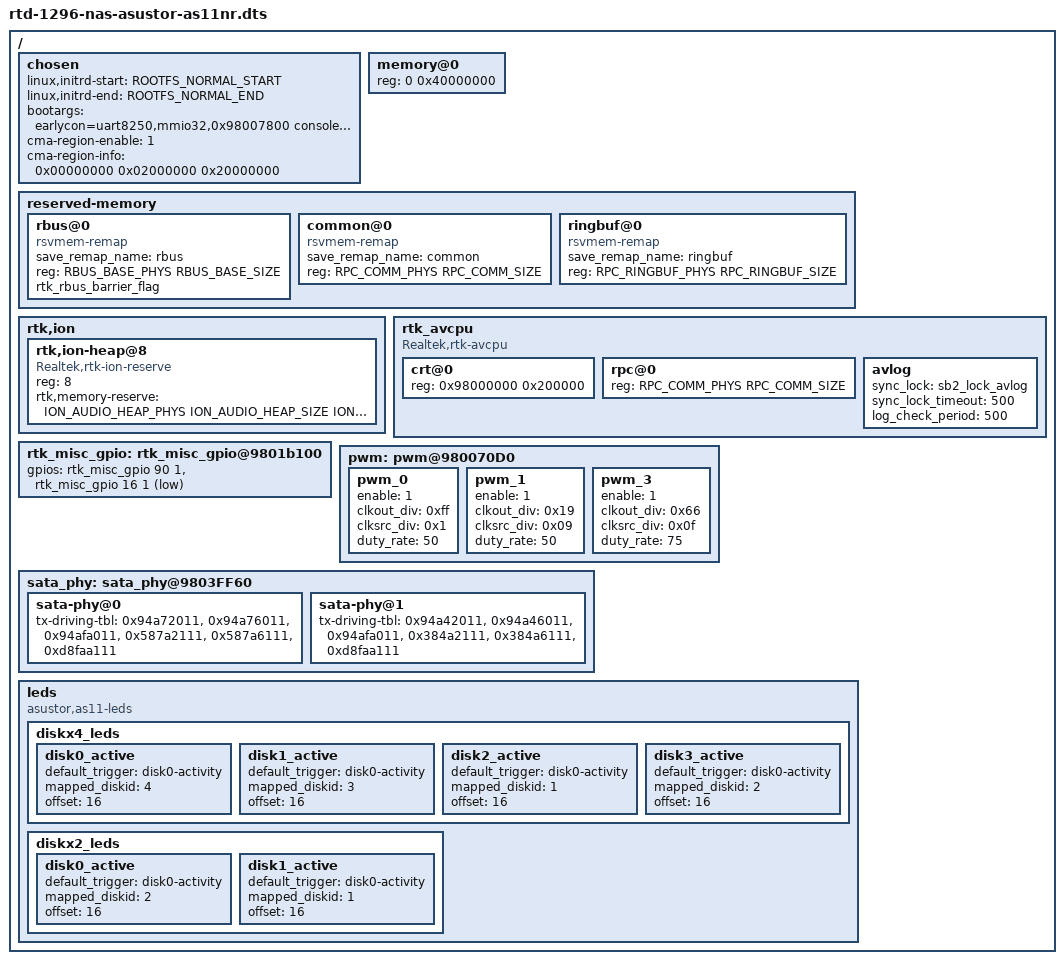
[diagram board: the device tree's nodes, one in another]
/dts-v1/;
#include <dt-bindings/soc/rtd129x,memory.h>

 /* 0x00000000 ~ 0x0002ffff */
/memreserve/ SYS_BOOTCODE_MEMBASE SYS_BOOTCODE_MEMSIZE;
/* 0x0001f000 ~ 0x0001ffff */
/memreserve/ RPC_COMM_PHYS RPC_COMM_SIZE;
/* 0x01ffe000 ~ 0x02001fff */
/memreserve/ RPC_RINGBUF_PHYS RPC_RINGBUF_SIZE;
 /* 0x02200000 ~ 0x025fffff */
/memreserve/ ROOTFS_NORMAL_START ROOTFS_NORMAL_SIZE;
/* 0x02600000 ~ 0x031fffff */
/memreserve/ ION_AUDIO_HEAP_PHYS ION_AUDIO_HEAP_SIZE;
/* 0x03200000 ~ 0x0e9fffff */
/memreserve/ ACPU_IDMEM_PHYS ACPU_IDMEM_SIZE;

#include "rtd-1296.dtsi"
#include "rtd-1296-asustor-common.dtsi"

/ {
	chosen {
		linux,initrd-start = <ROOTFS_NORMAL_START>;
		linux,initrd-end = <ROOTFS_NORMAL_END>;
		bootargs = "earlycon=uart8250,mmio32,0x98007800 console=ttyS0,115200 init=/init androidboot.hardware=kylin androidboot.storage=emmc loglevel=4";
	};

	/*
	 * NOTE:
	 * <flag size base>
	 * flag: reserved
	 * size: unit is byte
	 * base: unit is byte
	 *
	 * Array size not over 8;
	 * You may change the max array size in KConfig,
	 * max CMA array size is CONFIG_CMA_AREAS+1.
	 *
	 * If cma-region-enable is enabled<1>,
	 * kernel driver will use cma-region-info to initial CMA memory.
	 *
	 * If cma-region-enable is disabled<0>,
	 * kernel driver will use cma= to initial CMA memory.
	 *
	 * if both setting is loaded, cma-region-info had higher priority.
	 */
	chosen {
		cma-region-enable = <1>;
		cma-region-info = <0x00000000 0x02000000 0x20000000>;
		/*cma-region-info = <0x00000000 0x01000000 0x12c00000>,
			<0x00000000 0x12c00000 0x20000000>;*/
	};

	memory@0 {
		device_type = "memory";
		reg = <0 0x40000000>; /* 1024 MB */
	};

	reserved-memory {
		#address-cells = <1>;
		#size-cells = <1>;
		ranges;

		rbus@0 {
			compatible = "rsvmem-remap";
			save_remap_name = "rbus";
			reg = <RBUS_BASE_PHYS RBUS_BASE_SIZE>;
			rtk_rbus_barrier_flag;
		};

		common@0 {
			compatible = "rsvmem-remap";
			save_remap_name = "common";
			reg = <RPC_COMM_PHYS RPC_COMM_SIZE>;
		};

		ringbuf@0 {
			compatible = "rsvmem-remap";
			save_remap_name = "ringbuf";
			reg = <RPC_RINGBUF_PHYS RPC_RINGBUF_SIZE>;
		};
	};

	rtk,ion {
		rtk,ion-heap@8 { /* Audio */
			compatible = "Realtek,rtk-ion-reserve";
			reg = <8>;
			rtk,memory-reserve = <
				ION_AUDIO_HEAP_PHYS
				ION_AUDIO_HEAP_SIZE
				ION_AUDIO_HEAP_FLAG>;
		};
	};

	rtk_avcpu {
		compatible = "Realtek,rtk-avcpu";
		#address-cells = <1>;
		#size-cells = <1>;
		ranges;

		crt@0 {
			reg = <0x98000000 0x200000>;
		};

		rpc@0 {
			reg = <RPC_COMM_PHYS RPC_COMM_SIZE>;
		};

		avlog {
			sync_lock = <&sb2_lock_avlog>;
			sync_lock_timeout = <500>; /* ms */
			log_check_period = <500>; /* ms */
		};
	};
	
	rtk_misc_gpio: rtk_misc_gpio@9801b100 {
		gpios =
			<&rtk_misc_gpio 90 1 0>, /* Buzzer ON control, default: output, off */
			<&rtk_misc_gpio 16 1 1>; /* HDD1 indicate and active, default: output, on */
	};

	pwm: pwm@980070D0 {
		pwm_0 {
			/* Output all led brightness control */
			enable = <1>;
			clkout_div = <0xff>; //default OCD: from 0x0 to 0xff
			clksrc_div = <0x1>; //default OSD: from 0x0 to 0xf
			duty_rate = <50>; //default duty_rate 0 ~ 100
		};
		pwm_1 {
			/* Buzzer Speaker */
			enable = <1>;
			/* 1000 Hz */
			clkout_div = <0x19>; //default OCD: from 0x0 to 0xff
			clksrc_div = <0x09>; //default OSD: from 0x0 to 0xf
			duty_rate = <50>; //default duty_rate 0 ~ 100
		};
		pwm_3 {
			/* USB backup active indicate led (Steady, Blanking) */
			enable = <1>;
			/* 4 Hz */
			clkout_div = <0x66>; //default OCD: from 0x0 to 0xff
			clksrc_div = <0x0f>; //default OSD: from 0x0 to 0xf
			/* 50: Blanking, 75: Steady */
			duty_rate = <75>; //default duty_rate 0 ~ 100
		};
	};
	
	sata_phy: sata_phy@9803FF60 {
                sata-phy@0 {
                                        tx-driving-tbl = // user can define tx driving here //
                                        <0x94a72011>, <0x94a76011>, <0x94afa011>,
                                        <0x587a2111>, <0x587a6111>, <0xd8faa111>;
                };

                sata-phy@1 {
                                        tx-driving-tbl = // user can define tx driving here //
                                        <0x94a42011>, <0x94a46011>, <0x94afa011>,
                                        <0x384a2111>, <0x384a6111>, <0xd8faa111>;
                };
	};

	leds {
		compatible = "asustor,as11-leds";

		diskx4_leds {
			status = "okay";
			disk0_active {
				device_type = "gpio"; status = "okay"; default_trigger = "disk0-activity"; mapped_diskid = <4>; offset = <16>; };
			disk1_active {
				device_type = "gpio"; status = "okay"; default_trigger = "disk0-activity"; mapped_diskid = <3>; offset = <16>; };
			disk2_active {
				device_type = "gpio"; status = "okay"; default_trigger = "disk0-activity"; mapped_diskid = <1>; offset = <16>; };
			disk3_active {
				device_type = "gpio"; status = "okay"; default_trigger = "disk0-activity"; mapped_diskid = <2>; offset = <16>; };
		};

		diskx2_leds {
			status = "okay";
			disk0_active {
				device_type = "gpio"; status = "okay"; default_trigger = "disk0-activity"; mapped_diskid = <2>; offset = <16>; };
			disk1_active {
				device_type = "gpio"; status = "okay"; default_trigger = "disk0-activity"; mapped_diskid = <1>; offset = <16>; };
		};
	};
};

